# STM32F769NIH6 register map
File version: 1.0
STM32F769AGY6,STM32F769AIY6,STM32F769BGT6,STM32F769BIT6,STM32F769IGT6,STM32F769IIT6,STM32F769NGH6,STM32F769NIH6
Registers are 32-bit, access not given, reset 0x0 unless marked. A register's access mark holds for its fields unless they carry their own. Offsets are from the block's base; lines under a group give offsets from that group; [hi:lo] are bit positions; {n}, {i} and the like mark numbered series; 'fields as' and 'values as' point back to an identical list; <NAME> marks a mode.

## Memory map
0x40000000 TIM2
0x40000400 TIM3
0x40000800 TIM4
0x40000C00 TIM5
0x40001000 TIM6
0x40001400 TIM7
0x40001800 TIM12
0x40001C00 TIM13
0x40002000 TIM14
0x40002400 LPTIM1
0x40002800 RTC
0x40002C00 WWDG
0x40003000 IWDG
0x40003400 CAN3
0x40003800 SPI2
0x40003C00 SPI3
0x40004000 SPDIFRX
0x40004400 USART2
0x40004800 USART3
0x40004C00 UART4
0x40005000 UART5
0x40005400 I2C1
0x40005800 I2C2
0x40005C00 I2C3
0x40006000 I2C4
0x40006400 CAN1
0x40006800 CAN2
0x40006C00 CEC
0x40007000 PWR
0x40007400 DAC1
0x40007800 UART7
0x40007C00 UART8
0x40010000 TIM1
0x40010400 TIM8
0x40011000 USART1
0x40011400 USART6
0x40011C00 SDMMC2
0x40012000 ADC1
0x40012100 ADC2
0x40012200 ADC3
0x40012300 ADC
0x40012300 ADC123_COMMON
0x40012C00 SDMMC1
0x40013000 SPI1
0x40013400 SPI4
0x40013800 SYSCFG
0x40013C00 EXTI
0x40014000 TIM9
0x40014400 TIM10
0x40014800 TIM11
0x40015000 SPI5
0x40015400 SPI6
0x40015800 SAI1
0x40015C00 SAI2
0x40016800 LTDC
0x40016C00 DSI
0x40017400 DFSDM1
0x40017800 MDIOS
0x40020000 GPIOA
0x40020400 GPIOB
0x40020800 GPIOC
0x40020C00 GPIOD
0x40021000 GPIOE
0x40021400 GPIOF
0x40021800 GPIOG
0x40021C00 GPIOH
0x40022000 GPIOI
0x40022400 GPIOJ
0x40022800 GPIOK
0x40023000 CRC
0x40023800 RCC
0x40023C00 FLASH
0x40026000 DMA1
0x40026400 DMA2
0x40028000 ETH
0x4002B000 DMA2D
0x40040000 USB_OTG_HS
0x50000000 USB_OTG_FS
0x50050000 DCMI
0x50051000 JPEG
0x50060800 RNG
0xA0000000 FMC_Bank1
0xA0000080 FMC_Bank3
0xA0000104 FMC_Bank1E
0xA0000140 FMC_Bank5_6
0xA0001000 QUADSPI
0xE0042000 DBGMCU

## TIM2
Base 0x40000000
Same registers: TIM3 0x40000400, TIM4 0x40000800, TIM5 0x40000C00, TIM6 0x40001000, TIM7 0x40001400, TIM12 0x40001800, TIM13 0x40001C00, TIM14 0x40002000, TIM1 0x40010000, TIM8 0x40010400, TIM9 0x40014000, TIM10 0x40014400, TIM11 0x40014800
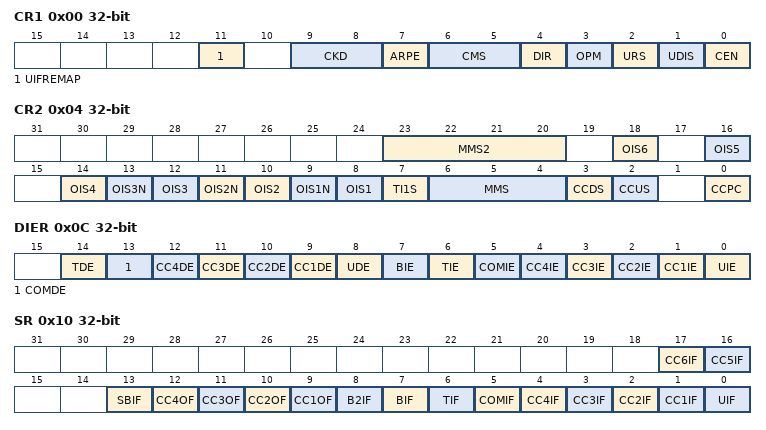
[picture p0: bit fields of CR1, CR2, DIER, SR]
0x00 CR1
  [11] UIFREMAP, [9:8] CKD, [7] ARPE, [6:5] CMS, [4] DIR, [3] OPM, [2] URS, [1] UDIS, [0] CEN
0x04 CR2
  [23:20] MMS2, [2n+6] OIS{n} (n=1..6), [13] OIS3N, [11] OIS2N, [9] OIS1N, [7] TI1S, [6:4] MMS, [3] CCDS, [2] CCUS, [0] CCPC
0x08 SMCR
  [15] ETP, [14] ECE, [13:12] ETPS, [11:8] ETF, [7] MSM, [6:4] TS, [16:0] SMS
0x0C DIER
  [14] TDE, [13] COMDE, [n+8] CC{n}DE (n=1..4), [8] UDE, [7] BIE, [6] TIE, [5] COMIE, [n] CC{n}IE (n=1..4), [0] UIE
0x10 SR
  [17] CC6IF, [16] CC5IF, [13] SBIF, [n+8] CC{n}OF (n=1..4), [8] B2IF, [7] BIF, [6] TIF, [5] COMIF, [n] CC{n}IF (n=1..4), [0] UIF
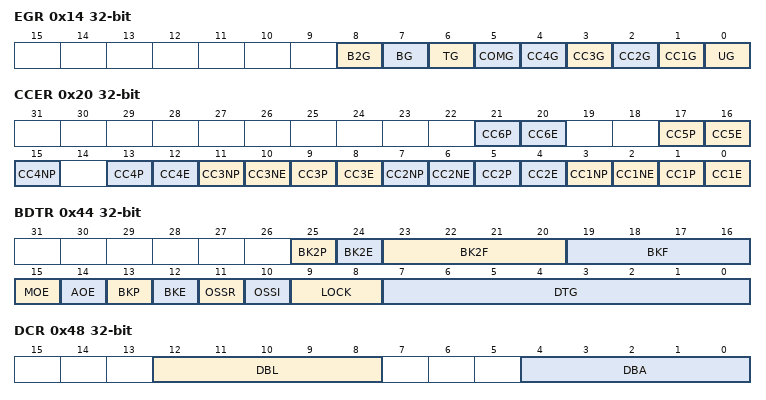
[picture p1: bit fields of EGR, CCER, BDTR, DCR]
0x14 EGR
  [8] B2G, [7] BG, [6] TG, [5] COMG, [n] CC{n}G (n=1..4), [0] UG
0x18 CCMR1
  [15] OC2CE, [24:12] OC2M, [11] OC2PE, [10] OC2FE, [9:8] CC2S, [7] OC1CE, [16:4] OC1M, [3] OC1PE, [2] OC1FE, [1:0] CC1S
0x1C CCMR2
  [15] OC4CE, [24:12] OC4M, [11] OC4PE, [10] OC4FE, [9:8] CC4S, [7] OC3CE, [16:4] OC3M, [3] OC3PE, [2] OC3FE, [1:0] CC3S
0x20 CCER
  [4n-3] CC{n}P (n=1..6), [4n-4] CC{n}E (n=1..6), [4n-1] CC{n}NP (n=1..4), [10] CC3NE, [6] CC2NE, [2] CC1NE
0x24 CNT
  [31] UIFCPY, [31:0] CNT
0x28 PSC
  [15:0] PSC
0x2C ARR
0x30 RCR
  [15:0] REP
{0x30+4i} CCR{i} (i=1..4)
  [15:0] CCR{i}
0x44 BDTR
  [25] BK2P, [24] BK2E, [23:20] BK2F, [19:16] BKF, [15] MOE, [14] AOE, [13] BKP, [12] BKE, [11] OSSR, [10] OSSI, [9:8] LOCK, [7:0] DTG
0x48 DCR
  [12:8] DBL, [4:0] DBA
0x4C DMAR
  [15:0] DMAB
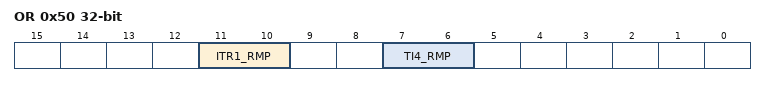
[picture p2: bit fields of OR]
0x50 OR
  [11:10] ITR1_RMP, [7:6] TI4_RMP
0x54 CCMR3
  [15] OC6CE, [24:12] OC6M, [11] OC6PE, [10] OC6FE, [7] OC5CE, [16:4] OC5M, [3] OC5PE, [2] OC5FE
0x58 CCR5
  [31] GC5C3, [30] GC5C2, [29] GC5C1, [31:0] CCR5
0x5C CCR6
0x60 AF1
0x64 AF2

## LPTIM1
Base 0x40002400
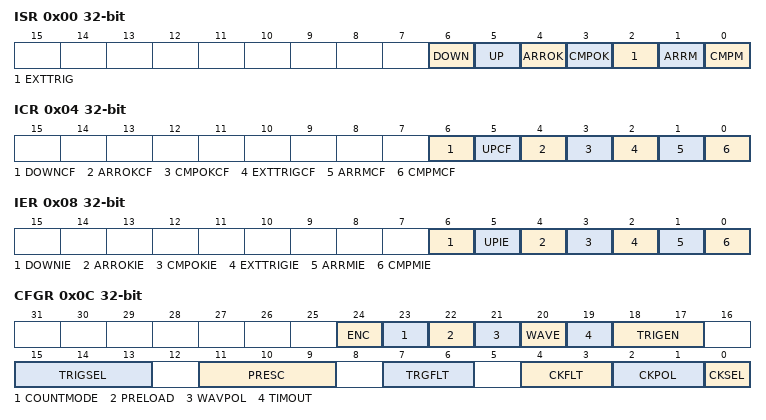
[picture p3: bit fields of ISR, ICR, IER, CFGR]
0x00 ISR
  [6] DOWN, [5] UP, [4] ARROK, [3] CMPOK, [2] EXTTRIG, [1] ARRM, [0] CMPM
0x04 ICR
  [6] DOWNCF, [5] UPCF, [4] ARROKCF, [3] CMPOKCF, [2] EXTTRIGCF, [1] ARRMCF, [0] CMPMCF
0x08 IER
  [6] DOWNIE, [5] UPIE, [4] ARROKIE, [3] CMPOKIE, [2] EXTTRIGIE, [1] ARRMIE, [0] CMPMIE
0x0C CFGR
  [24] ENC, [23] COUNTMODE, [22] PRELOAD, [21] WAVPOL, [20] WAVE, [19] TIMOUT, [18:17] TRIGEN, [15:13] TRIGSEL, [11:9] PRESC, [7:6] TRGFLT, [4:3] CKFLT, [2:1] CKPOL, [0] CKSEL
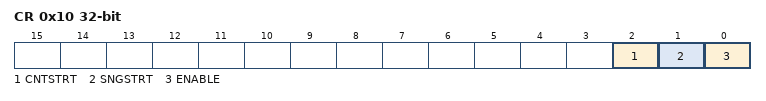
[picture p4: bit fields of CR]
0x10 CR
  [2] CNTSTRT, [1] SNGSTRT, [0] ENABLE
0x14 CMP
  [15:0] CMP
0x18 ARR
  [15:0] ARR
0x1C CNT
  [15:0] CNT
